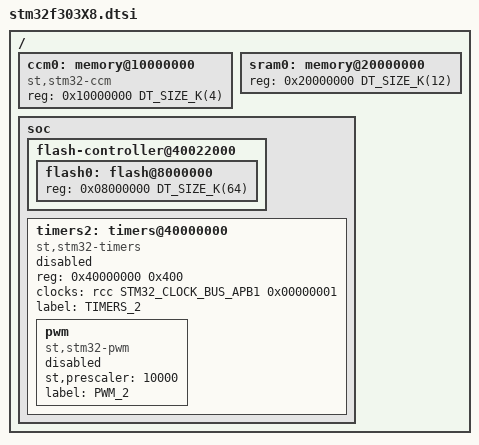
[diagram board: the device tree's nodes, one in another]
/*
 * Copyright (c) 2018 Linaro Limited
 *
 * SPDX-License-Identifier: Apache-2.0
 */

#include <mem.h>
#include <st/f3/stm32f303.dtsi>

/ {
	ccm0: memory@10000000 {
		compatible = "st,stm32-ccm";
		reg = <0x10000000 DT_SIZE_K(4)>;
	};

	sram0: memory@20000000 {
		reg = <0x20000000 DT_SIZE_K(12)>;
	};

	soc {
		flash-controller@40022000 {
			flash0: flash@8000000 {
				reg = <0x08000000 DT_SIZE_K(64)>;
			};
		};
	timers2: timers@40000000 {
			compatible = "st,stm32-timers";
			reg = <0x40000000 0x400>;
			clocks = <&rcc STM32_CLOCK_BUS_APB1 0x00000001>;
			status = "disabled";
			label = "TIMERS_2";

			pwm {
				compatible = "st,stm32-pwm";
				status = "disabled";
				st,prescaler = <10000>;
				label = "PWM_2";
				#pwm-cells = <2>;
			};
		};
	};
};
